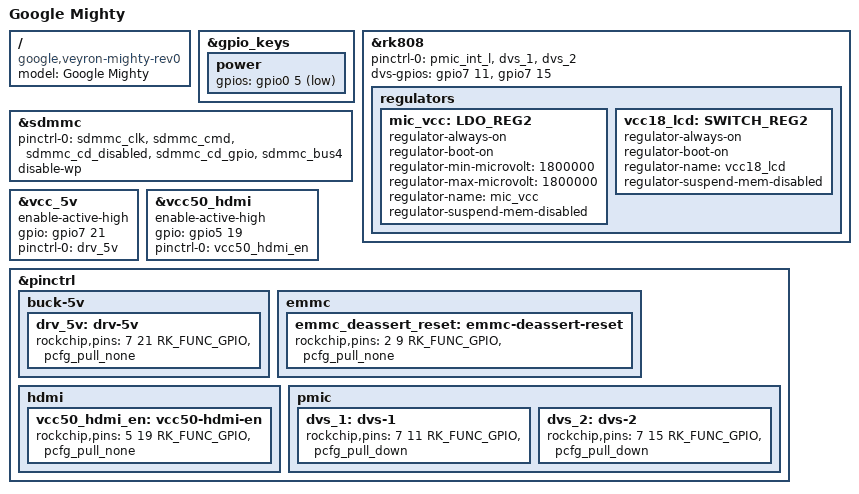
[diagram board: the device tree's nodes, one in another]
/*
 * Google Veyron Mighty Rev 1 board device tree source
 *
 * Copyright 2014 Google, Inc
 *
 * This program is free software; you can redistribute it and/or modify
 * it under the terms of the GNU General Public License version 2 as
 * published by the Free Software Foundation.
 */

/dts-v1/;
#include "rk3288-veyron.dtsi"
#include "cros-ec-sbs.dtsi"

/ {
	model = "Google Mighty";
	compatible = "google,veyron-mighty-rev0", "google,veyron-mighty",
		     "google,veyron", "rockchip,rk3288";
};

&gpio_keys {
	power {
		gpios = <&gpio0 5 GPIO_ACTIVE_LOW>;
	};
};

&rk808 {
	pinctrl-names = "default";
	pinctrl-0 = <&pmic_int_l &dvs_1 &dvs_2>;
	dvs-gpios = <&gpio7 11 GPIO_ACTIVE_HIGH>,
		    <&gpio7 15 GPIO_ACTIVE_HIGH>;

	regulators {
		mic_vcc: LDO_REG2 {
			regulator-always-on;
			regulator-boot-on;
			regulator-min-microvolt = <1800000>;
			regulator-max-microvolt = <1800000>;
			regulator-name = "mic_vcc";
			regulator-suspend-mem-disabled;
		};

		vcc18_lcd: SWITCH_REG2 {
			regulator-always-on;
			regulator-boot-on;
			regulator-name = "vcc18_lcd";
			regulator-suspend-mem-disabled;
		};
	};
};

&sdmmc {
	pinctrl-names = "default";
	pinctrl-0 = <&sdmmc_clk &sdmmc_cmd &sdmmc_cd_disabled &sdmmc_cd_gpio
			&sdmmc_bus4>;
	disable-wp;
};

&vcc_5v {
	enable-active-high;
	gpio = <&gpio7 21 GPIO_ACTIVE_HIGH>;
	pinctrl-names = "default";
	pinctrl-0 = <&drv_5v>;
};

&vcc50_hdmi {
	enable-active-high;
	gpio = <&gpio5 19 GPIO_ACTIVE_HIGH>;
	pinctrl-names = "default";
	pinctrl-0 = <&vcc50_hdmi_en>;
};

&pinctrl {
	buck-5v {
		drv_5v: drv-5v {
			rockchip,pins = <7 21 RK_FUNC_GPIO &pcfg_pull_none>;
		};
	};

	emmc {
		/* Make sure eMMC is not in reset */
		emmc_deassert_reset: emmc-deassert-reset {
			rockchip,pins = <2 9 RK_FUNC_GPIO &pcfg_pull_none>;
		};
	};

	hdmi {
		vcc50_hdmi_en: vcc50-hdmi-en {
			rockchip,pins = <5 19 RK_FUNC_GPIO &pcfg_pull_none>;
		};
	};

	pmic {
		dvs_1: dvs-1 {
			rockchip,pins = <7 11 RK_FUNC_GPIO &pcfg_pull_down>;
		};

		dvs_2: dvs-2 {
			rockchip,pins = <7 15 RK_FUNC_GPIO &pcfg_pull_down>;
		};
	};
};
